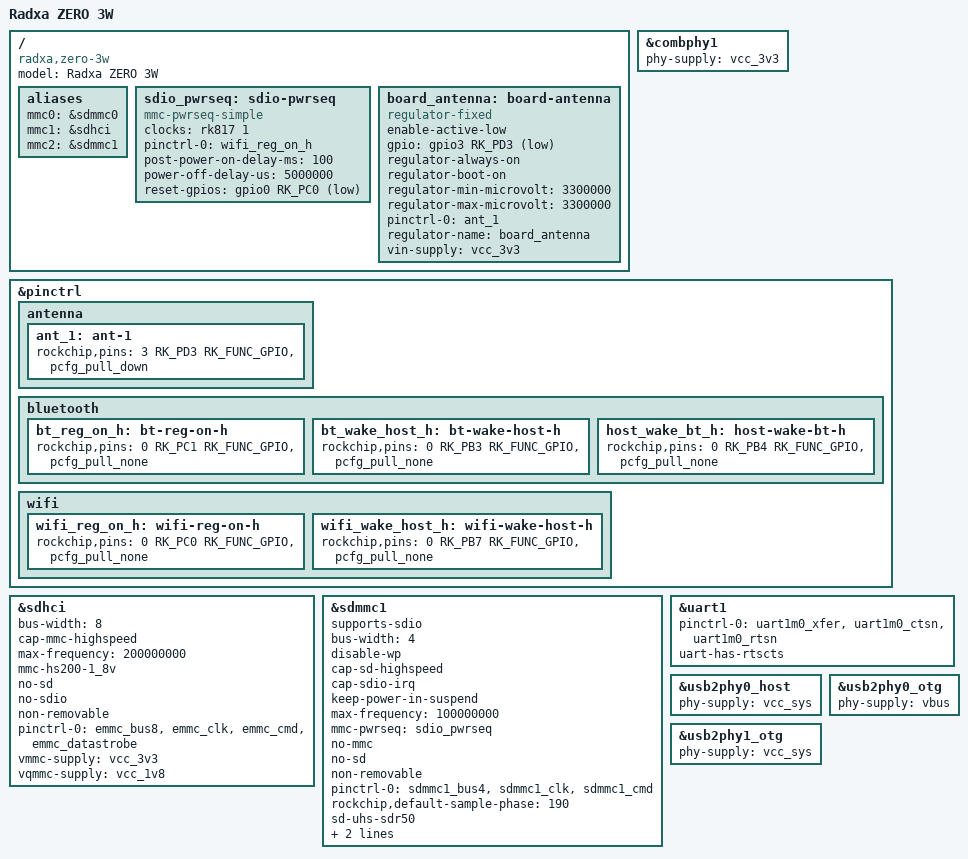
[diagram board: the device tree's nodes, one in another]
// SPDX-License-Identifier: (GPL-2.0+ OR MIT)

/dts-v1/;

#include "rk3566-radxa-zero-3.dtsi"

/ {
	model = "Radxa ZERO 3W";
	compatible = "radxa,zero-3w", "rockchip,rk3566";

	aliases {
		/* SD card */
		mmc0 = &sdmmc0;
		/* eMMC */
		mmc1 = &sdhci;
		/* WiFi SDIO */
		mmc2 = &sdmmc1;
	};

	sdio_pwrseq: sdio-pwrseq {
		compatible = "mmc-pwrseq-simple";
		clocks = <&rk817 1>;
		clock-names = "ext_clock";
		pinctrl-names = "default";
		pinctrl-0 = <&wifi_reg_on_h>;
		post-power-on-delay-ms = <100>;
		power-off-delay-us = <5000000>;
		reset-gpios = <&gpio0 RK_PC0 GPIO_ACTIVE_LOW>;
	};

	board_antenna: board-antenna {
		compatible = "regulator-fixed";
		enable-active-low;
		gpio = <&gpio3 RK_PD3 GPIO_ACTIVE_LOW>;
		regulator-always-on;
		regulator-boot-on;
		regulator-min-microvolt = <3300000>;
		regulator-max-microvolt = <3300000>;
		pinctrl-0 = <&ant_1>;
		pinctrl-names = "default";
		regulator-name = "board_antenna";
		status = "okay";
		vin-supply = <&vcc_3v3>;
	};
};

&combphy1 {
	phy-supply = <&vcc_3v3>;
	status = "okay";
};

&pinctrl {
	antenna {
		ant_1: ant-1 {
			rockchip,pins = <3 RK_PD3 RK_FUNC_GPIO &pcfg_pull_down>;
		};
	};

	bluetooth {
		bt_reg_on_h: bt-reg-on-h {
			rockchip,pins = <0 RK_PC1 RK_FUNC_GPIO &pcfg_pull_none>;
		};

		bt_wake_host_h: bt-wake-host-h {
			rockchip,pins = <0 RK_PB3 RK_FUNC_GPIO &pcfg_pull_none>;
		};

		host_wake_bt_h: host-wake-bt-h {
			rockchip,pins = <0 RK_PB4 RK_FUNC_GPIO &pcfg_pull_none>;
		};
	};

	wifi {
		wifi_reg_on_h: wifi-reg-on-h {
			rockchip,pins = <0 RK_PC0 RK_FUNC_GPIO &pcfg_pull_none>;
		};

		wifi_wake_host_h: wifi-wake-host-h {
			rockchip,pins = <0 RK_PB7 RK_FUNC_GPIO &pcfg_pull_none>;
		};
	};
};

&sdhci {
	bus-width = <8>;
	cap-mmc-highspeed;
	max-frequency = <200000000>;
	mmc-hs200-1_8v;
	no-sd;
	no-sdio;
	non-removable;
	pinctrl-names = "default";
	pinctrl-0 = <&emmc_bus8 &emmc_clk &emmc_cmd &emmc_datastrobe>;
	vmmc-supply = <&vcc_3v3>;
	vqmmc-supply = <&vcc_1v8>;
	status = "okay";
};

&sdmmc1 {
	supports-sdio;
	bus-width = <4>;
	disable-wp;
	cap-sd-highspeed;
	cap-sdio-irq;
	keep-power-in-suspend;
	max-frequency = <100000000>;
	mmc-pwrseq = <&sdio_pwrseq>;
	no-mmc;
	no-sd;
	non-removable;
	pinctrl-names = "default";
	pinctrl-0 = <&sdmmc1_bus4 &sdmmc1_clk &sdmmc1_cmd>;
	rockchip,default-sample-phase = <190>;
	sd-uhs-sdr50;
	vmmc-supply = <&vcc_3v3>;
	vqmmc-supply = <&vcc_1v8>;
	status = "okay";
};

&uart1 {
	pinctrl-names = "default";
	pinctrl-0 = <&uart1m0_xfer &uart1m0_ctsn &uart1m0_rtsn>;
	uart-has-rtscts;
	status = "okay";
};

&usb2phy0_host {
	phy-supply = <&vcc_sys>;
	status = "okay";
};

&usb2phy0_otg {
	phy-supply = <&vbus>;
	status = "okay";
};

&usb2phy1_otg {
	phy-supply = <&vcc_sys>;
	status = "okay";
};
